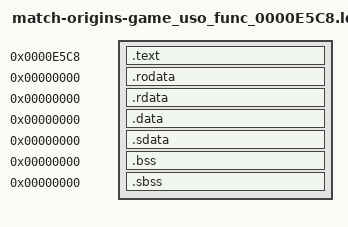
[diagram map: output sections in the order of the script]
/* Standard linker bindings; original USO identity is independently audited. */
SECTIONS {
 .text 0xe5c8 : SUBALIGN(4) { *(.text) *(.text.*) }
 .rodata 0x0 : SUBALIGN(4) { *(.rodata) *(.rodata.*) }
 .rdata 0x0 : SUBALIGN(4) { *(.rdata) *(.rdata.*) }
 .data 0x0 : SUBALIGN(4) { *(.data) *(.data.*) }
 .sdata 0x0 : SUBALIGN(4) { *(.sdata) *(.sdata.*) }
 .bss 0x0 : SUBALIGN(4) { *(.bss) *(.bss.*) }
 .sbss 0x0 : SUBALIGN(4) { *(.sbss) *(.sbss.*) }
 /DISCARD/ : { *(.mdebug) *(.reginfo) *(.pdr) *(.comment) *(.MIPS.abiflags) *(.options) }
}
game_uso_D_807FFBC0 = 0x0;
game_uso_e5c8_count = 0x0;
game_uso_e5c8_eaf4 = 0x0;
